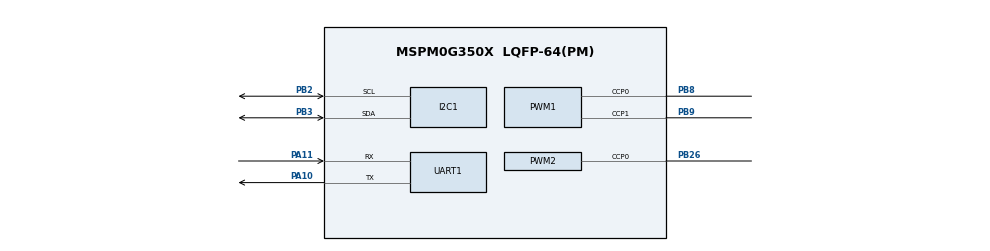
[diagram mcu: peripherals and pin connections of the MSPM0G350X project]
/**
 *
 * @cliArgs --device "MSPM0G350X" --part "Default" --package "LQFP-64(PM)" --product "mspm0_sdk@2.10.00.04"
 * @versions {"tool":"1.28.0+4696"}
 */

/**
 * Import the modules used in this configuration.
 */
const GPIO    = scripting.addModule("/ti/driverlib/GPIO", {}, false);
const GPIO1   = GPIO.addInstance();
const GPIO2   = GPIO.addInstance();
const GPIO3   = GPIO.addInstance();
const GPIO4   = GPIO.addInstance();
const GPIO5   = GPIO.addInstance();
const I2C     = scripting.addModule("/ti/driverlib/I2C", {}, false);
const I2C1    = I2C.addInstance();
const PWM     = scripting.addModule("/ti/driverlib/PWM", {}, false);
const PWM1    = PWM.addInstance();
const PWM2    = PWM.addInstance();
const SYSCTL  = scripting.addModule("/ti/driverlib/SYSCTL");
const SYSTICK = scripting.addModule("/ti/driverlib/SYSTICK");
const TIMER   = scripting.addModule("/ti/driverlib/TIMER", {}, false);
const TIMER1  = TIMER.addInstance();
const UART    = scripting.addModule("/ti/driverlib/UART", {}, false);
const UART1   = UART.addInstance();

/**
 * Write custom configuration values to the imported modules.
 */
GPIO1.$name                          = "GPIO_Motor";
GPIO1.associatedPins.create(5);
GPIO1.associatedPins[0].$name        = "AIN1";
GPIO1.associatedPins[0].assignedPin  = "0";
GPIO1.associatedPins[0].assignedPort = "PORTB";
GPIO1.associatedPins[1].$name        = "AIN2";
GPIO1.associatedPins[1].assignedPin  = "1";
GPIO1.associatedPins[1].assignedPort = "PORTB";
GPIO1.associatedPins[2].$name        = "BIN1";
GPIO1.associatedPins[2].assignedPin  = "4";
GPIO1.associatedPins[2].assignedPort = "PORTB";
GPIO1.associatedPins[3].$name        = "BIN2";
GPIO1.associatedPins[3].assignedPin  = "5";
GPIO1.associatedPins[3].assignedPort = "PORTB";
GPIO1.associatedPins[4].$name        = "STBY";
GPIO1.associatedPins[4].assignedPin  = "6";
GPIO1.associatedPins[4].assignedPort = "PORTB";

const Board = scripting.addModule("/ti/driverlib/Board", {}, false);

GPIO2.$name                              = "GPIO_Encoder";
GPIO2.associatedPins.create(4);
GPIO2.associatedPins[0].$name            = "EncoderL_A";
GPIO2.associatedPins[0].direction        = "INPUT";
GPIO2.associatedPins[0].internalResistor = "PULL_UP";
GPIO2.associatedPins[0].assignedPort     = "PORTB";
GPIO2.associatedPins[0].assignedPin      = "12";
GPIO2.associatedPins[1].$name            = "EncoderL_B";
GPIO2.associatedPins[1].direction        = "INPUT";
GPIO2.associatedPins[1].internalResistor = "PULL_UP";
GPIO2.associatedPins[1].assignedPort     = "PORTB";
GPIO2.associatedPins[1].assignedPin      = "13";
GPIO2.associatedPins[1].interruptEn      = true;
GPIO2.associatedPins[1].polarity         = "RISE";
GPIO2.associatedPins[2].$name            = "EncoderR_A";
GPIO2.associatedPins[2].direction        = "INPUT";
GPIO2.associatedPins[2].internalResistor = "PULL_UP";
GPIO2.associatedPins[2].assignedPort     = "PORTB";
GPIO2.associatedPins[2].assignedPin      = "20";
GPIO2.associatedPins[3].$name            = "EncoderR_B";
GPIO2.associatedPins[3].direction        = "INPUT";
GPIO2.associatedPins[3].internalResistor = "PULL_UP";
GPIO2.associatedPins[3].assignedPort     = "PORTB";
GPIO2.associatedPins[3].assignedPin      = "7";
GPIO2.associatedPins[3].interruptEn      = true;
GPIO2.associatedPins[3].polarity         = "RISE";

GPIO3.$name                              = "GPIO_GraySensor";
GPIO3.associatedPins.create(2);
GPIO3.associatedPins[0].$name            = "CLK";
GPIO3.associatedPins[0].assignedPort     = "PORTA";
GPIO3.associatedPins[0].assignedPin      = "13";
GPIO3.associatedPins[1].$name            = "DAT";
GPIO3.associatedPins[1].direction        = "INPUT";
GPIO3.associatedPins[1].internalResistor = "PULL_UP";
GPIO3.associatedPins[1].assignedPort     = "PORTA";
GPIO3.associatedPins[1].assignedPin      = "12";

GPIO4.$name                              = "GPIO_KEY";
GPIO4.associatedPins[0].$name            = "START";
GPIO4.associatedPins[0].direction        = "INPUT";
GPIO4.associatedPins[0].internalResistor = "PULL_UP";
GPIO4.associatedPins[0].assignedPort     = "PORTB";
GPIO4.associatedPins[0].assignedPin      = "21";

GPIO5.$name                          = "GPIO_LED";
GPIO5.associatedPins[0].$name        = "STATUS";
GPIO5.associatedPins[0].assignedPort = "PORTB";
GPIO5.associatedPins[0].assignedPin  = "27";

I2C1.$name                           = "I2C_0";
I2C1.basicEnableController           = true;
I2C1.basicControllerStandardBusSpeed = "Fast";
I2C1.peripheral.$assign              = "I2C1";
I2C1.peripheral.sdaPin.$assign       = "PB3";
I2C1.peripheral.sclPin.$assign       = "PB2";
I2C1.sdaPinConfig.$name              = "ti_driverlib_gpio_GPIOPinGeneric4";
I2C1.sclPinConfig.$name              = "ti_driverlib_gpio_GPIOPinGeneric5";

PWM1.$name                              = "PWM_Motors";
PWM1.clockDivider                       = 4;
PWM1.peripheral.$assign                 = "TIMA0";
PWM1.peripheral.ccp0Pin.$assign         = "PB8";
PWM1.peripheral.ccp1Pin.$assign         = "PB9";
PWM1.PWM_CHANNEL_0.$name                = "ti_driverlib_pwm_PWMTimerCC0";
PWM1.PWM_CHANNEL_1.$name                = "ti_driverlib_pwm_PWMTimerCC1";
PWM1.ccp0PinConfig.$name                = "ti_driverlib_gpio_GPIOPinGeneric0";
PWM1.ccp0PinConfig.direction            = scripting.forceWrite("OUTPUT");
PWM1.ccp0PinConfig.hideOutputInversion  = scripting.forceWrite(false);
PWM1.ccp0PinConfig.onlyInternalResistor = scripting.forceWrite(false);
PWM1.ccp0PinConfig.passedPeripheralType = scripting.forceWrite("Digital");
PWM1.ccp1PinConfig.$name                = "ti_driverlib_gpio_GPIOPinGeneric1";
PWM1.ccp1PinConfig.direction            = scripting.forceWrite("OUTPUT");
PWM1.ccp1PinConfig.hideOutputInversion  = scripting.forceWrite(false);
PWM1.ccp1PinConfig.onlyInternalResistor = scripting.forceWrite(false);
PWM1.ccp1PinConfig.passedPeripheralType = scripting.forceWrite("Digital");

PWM2.$name                              = "PWM_Buzzer";
PWM2.ccIndex                            = [0];
PWM2.clockDivider                       = 8;
PWM2.clockPrescale                      = 32;
PWM2.timerCount                         = 100;
PWM2.PWM_CHANNEL_0.$name                = "ti_driverlib_pwm_PWMTimerCC2";
PWM2.ccp0PinConfig.$name                = "ti_driverlib_gpio_GPIOPinGeneric2";
PWM2.ccp0PinConfig.direction            = scripting.forceWrite("OUTPUT");
PWM2.ccp0PinConfig.hideOutputInversion  = scripting.forceWrite(false);
PWM2.ccp0PinConfig.onlyInternalResistor = scripting.forceWrite(false);
PWM2.ccp0PinConfig.passedPeripheralType = scripting.forceWrite("Digital");
PWM2.peripheral.$assign                 = "TIMG6";
PWM2.peripheral.ccp0Pin.$assign         = "PB26";

SYSCTL.forceDefaultClkConfig = true;
SYSCTL.SYSPLL_CLK2XEn        = true;
SYSCTL.MCLKSource            = "HSCLK";
SYSCTL.HSCLKSource           = "SYSPLLCLK2X";
SYSCTL.SYSPLL_CLK2XDiv       = 3;

TIMER1.$name              = "TIM_CTRL";
TIMER1.timerMode          = "PERIODIC";
TIMER1.timerPeriod        = "5 ms";
TIMER1.interrupts         = ["ZERO"];
TIMER1.timerClkDiv        = 8;
TIMER1.timerClkPrescale   = 32;
TIMER1.peripheral.$assign = "TIMG7";

UART1.$name                            = "UART0_Debug";
UART1.targetBaudRate                   = 115200;
UART1.peripheral.rxPin.$assign         = "PA11";
UART1.peripheral.txPin.$assign         = "PA10";
UART1.txPinConfig.$name                = "ti_driverlib_gpio_GPIOPinGeneric6";
UART1.txPinConfig.direction            = scripting.forceWrite("OUTPUT");
UART1.txPinConfig.hideOutputInversion  = scripting.forceWrite(false);
UART1.txPinConfig.onlyInternalResistor = scripting.forceWrite(false);
UART1.txPinConfig.passedPeripheralType = scripting.forceWrite("Digital");
UART1.rxPinConfig.$name                = "ti_driverlib_gpio_GPIOPinGeneric7";
UART1.rxPinConfig.hideOutputInversion  = scripting.forceWrite(false);
UART1.rxPinConfig.onlyInternalResistor = scripting.forceWrite(false);
UART1.rxPinConfig.passedPeripheralType = scripting.forceWrite("Digital");

/**
 * Pinmux solution for unlocked pins/peripherals. This ensures that minor changes to the automatic solver in a future
 * version of the tool will not impact the pinmux you originally saw.  These lines can be completely deleted in order to
 * re-solve from scratch.
 */
GPIO1.associatedPins[0].pin.$suggestSolution = "PB0";
GPIO1.associatedPins[1].pin.$suggestSolution = "PB1";
GPIO1.associatedPins[2].pin.$suggestSolution = "PB4";
GPIO1.associatedPins[3].pin.$suggestSolution = "PB5";
GPIO1.associatedPins[4].pin.$suggestSolution = "PB6";
Board.peripheral.$suggestSolution            = "DEBUGSS";
Board.peripheral.swclkPin.$suggestSolution   = "PA20";
Board.peripheral.swdioPin.$suggestSolution   = "PA19";
GPIO2.associatedPins[0].pin.$suggestSolution = "PB12";
GPIO2.associatedPins[1].pin.$suggestSolution = "PB13";
GPIO2.associatedPins[2].pin.$suggestSolution = "PB20";
GPIO2.associatedPins[3].pin.$suggestSolution = "PB7";
GPIO3.associatedPins[0].pin.$suggestSolution = "PA13";
GPIO3.associatedPins[1].pin.$suggestSolution = "PA12";
GPIO4.associatedPins[0].pin.$suggestSolution = "PB21";
GPIO5.associatedPins[0].pin.$suggestSolution = "PB27";
SYSCTL.peripheral.$suggestSolution           = "SYSCTL";
UART1.peripheral.$suggestSolution            = "UART0";
